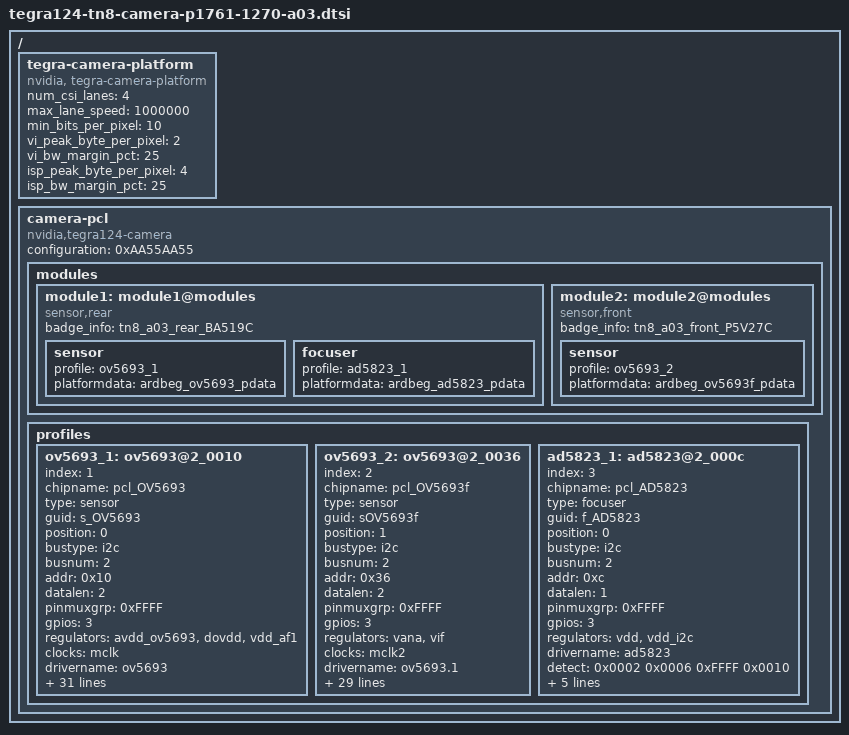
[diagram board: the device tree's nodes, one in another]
/*
 * Copyright (c) 2016, NVIDIA CORPORATION.  All rights reserved.
 *
 * This program is free software; you can redistribute it and/or modify it
 * under the terms and conditions of the GNU General Public License,
 * version 2, as published by the Free Software Foundation.
 *
 * This program is distributed in the hope it will be useful, but WITHOUT
 * ANY WARRANTY; without even the implied warranty of MERCHANTABILITY or
 * FITNESS FOR A PARTICULAR PURPOSE.  See the GNU General Public License for
 * more details.
 *
 * arch/arm/boot/dts/tegra124-platforms/tegra124-tn8-camera-p1761-1270-a00.dtsi
 */

#include <dt-bindings/media/camera.h>

/ {
	tegra-camera-platform {
		compatible = "nvidia, tegra-camera-platform";
		/**
		* Physical settings to calculate max ISO BW
		*
		* num_csi_lanes = <>;
		* Total number of CSI lanes when all cameras are active
		*
		* max_lane_speed = <>;
		* Max lane speed in Kbit/s
		*
		* min_bits_per_pixel = <>;
		* Min bits per pixel
		*
		* vi_peak_byte_per_pixel = <>;
		* Max byte per pixel for the VI ISO case
		*
		* vi_bw_margin_pct = <>;
		* Vi bandwidth margin in percentage
		*
		* isp_peak_byte_per_pixel = <>;
		* Max byte per pixel for the ISP ISO case
		*
		* isp_bw_margin_pct = <>;
		* Isp bandwidth margin in percentage
		*/
		num_csi_lanes = <4>;
		max_lane_speed = <1000000>;
		min_bits_per_pixel = <10>;
		vi_peak_byte_per_pixel = <2>;
		vi_bw_margin_pct = <25>;
		isp_peak_byte_per_pixel = <4>;
		isp_bw_margin_pct = <25>;
	};

	camera-pcl {
		compatible = "nvidia,tegra124-camera", "simple-bus";
		configuration = <0xAA55AA55>;

		modules {
			module1: module1@modules {
				compatible = "sensor,rear";
				badge_info = "tn8_a03_rear_BA519C";

				sensor {
					profile = <&ov5693_1>;
					platformdata = "ardbeg_ov5693_pdata";
				};
				focuser {
					profile = <&ad5823_1>;
					platformdata = "ardbeg_ad5823_pdata";
				};
			};
			module2: module2@modules {
				compatible = "sensor,front";
				badge_info = "tn8_a03_front_P5V27C";

				sensor {
					profile = <&ov5693_2>;
					platformdata = "ardbeg_ov5693f_pdata";
				};
			};
		};

		profiles {
			ov5693_1: ov5693@2_0010 {
				index = <1>;
				chipname = "pcl_OV5693";
				type = "sensor";
				guid = "s_OV5693";
				position = <0>;
				bustype = "i2c";
				busnum = <2>;
				addr = <0x10>;
				datalen = <2>;
				pinmuxgrp = <0xFFFF>;
				gpios = <3>;
				regulators = "avdd_ov5693", "dovdd", "vdd_af1";
				clocks = "mclk";
				drivername = "ov5693";
				detect = <0x0002 0x300A 0xFFFF 0x5690>;
				devid = <0x5693>;
				poweron = <
					CAMERA_IND_CLK_SET(10000)
					CAMERA_GPIO_CLR(221)
					CAMERA_WAITMS(1)
					CAMERA_REGULATOR_ON(0)
					CAMERA_REGULATOR_ON(2)
					CAMERA_REGULATOR_ON(1)
					CAMERA_WAITMS(1)
					CAMERA_GPIO_SET(221)
					CAMERA_WAITMS(10)
					CAMERA_END
					>;
				poweroff = <
					CAMERA_IND_CLK_CLR
					CAMERA_GPIO_CLR(221)
					CAMERA_WAITUS(10)
					CAMERA_REGULATOR_OFF(1)
					CAMERA_REGULATOR_OFF(2)
					CAMERA_REGULATOR_OFF(0)
					CAMERA_END
					>;
				/* sensor capabilities */
				cap-version = <0x34340002>;
				cap-identifier = "OV5693";
				cap-sensor_nvc_interface = <3>;
				cap-pixel_types = <0x2101>;
				cap-orientation = <1>;
				cap-direction = <0>;
				cap-initial_clock_rate_khz = <6000>;
				cap-h_sync_edge = <0>;
				cap-v_sync_edge = <0>;
				cap-mclk_on_vgp0 = <0>;
				cap-csi_port = <0>;
				cap-data_lanes = <2>;
				cap-virtual_channel_id = <0>;
				cap-discontinuous_clk_mode = <1>;
				cap-cil_threshold_settle = <0>;
				cap-min_blank_time_width = <16>;
				cap-min_blank_time_height = <16>;
				cap-preferred_mode_index = <0>;
				cap-external_clock_khz_0 = <24000>;
				cap-clock_multiplier_0 = <8000000>;
				cap-external_clock_khz_1 = <0>;
				cap-clock_multiplier_1 = <0>;
				cap-hdr-enabled;
				cap-focuser_guid = <
					0x665f4144
					0x35383233
				>;
				cap-torch_guid = <
					0x6c5f4e56
					0x43414d30
				>;
			};
			ov5693_2: ov5693@2_0036 {
				index = <2>;
				chipname = "pcl_OV5693f";
				type = "sensor";
				guid = "sOV5693f";
				position = <1>;
				bustype = "i2c";
				busnum = <2>;
				addr = <0x36>;
				datalen = <2>;
				pinmuxgrp = <0xFFFF>;
				gpios = <3>;
				regulators = "vana", "vif";
				clocks = "mclk2";
				drivername = "ov5693.1";
				detect = <0x0002 0x300A 0xFFFF 0x5690>;
				devid = <0x5693>;
				poweron = <
					CAMERA_IND_CLK_SET(10000)
					CAMERA_GPIO_CLR(219)
					CAMERA_GPIO_CLR(222)
					CAMERA_WAITMS(1)
					CAMERA_REGULATOR_ON(0)
					CAMERA_REGULATOR_ON(1)
					CAMERA_WAITMS(1)
					CAMERA_GPIO_SET(222)
					CAMERA_GPIO_SET(219)
					CAMERA_WAITMS(10)
					CAMERA_END
					>;
				poweroff = <
					CAMERA_IND_CLK_CLR
					CAMERA_GPIO_CLR(222)
					CAMERA_GPIO_CLR(219)
					CAMERA_WAITUS(10)
					CAMERA_REGULATOR_OFF(1)
					CAMERA_REGULATOR_OFF(0)
					CAMERA_END
					>;
				/* sensor capabilities */
				cap-version = <0x34340002>;
				cap-identifier = "OV5693.1";
				cap-sensor_nvc_interface = <4>;
				cap-pixel_types = <0x2101>;
				cap-orientation = <3>;
				cap-direction = <1>;
				cap-initial_clock_rate_khz = <6000>;
				cap-h_sync_edge = <0>;
				cap-v_sync_edge = <0>;
				cap-mclk_on_vgp0 = <0>;
				cap-csi_port = <1>;
				cap-data_lanes = <2>;
				cap-virtual_channel_id = <0>;
				cap-discontinuous_clk_mode = <1>;
				cap-cil_threshold_settle = <0>;
				cap-min_blank_time_width = <16>;
				cap-min_blank_time_height = <16>;
				cap-preferred_mode_index = <0>;
				cap-external_clock_khz_0 = <24000>;
				cap-clock_multiplier_0 = <8000000>;
				cap-external_clock_khz_1 = <0>;
				cap-clock_multiplier_1 = <0>;
				cap-hdr-enabled;
			};
			ad5823_1: ad5823@2_000c {
				index = <3>;
				chipname = "pcl_AD5823";
				type = "focuser";
				guid = "f_AD5823";
				position = <0>;
				bustype = "i2c";
				busnum = <2>;
				addr = <0xc>;
				datalen = <1>;
				pinmuxgrp = <0xFFFF>;
				gpios = <3>;
				regulators = "vdd", "vdd_i2c";
				drivername = "ad5823";
				detect = <0x0002 0x0006 0xFFFF 0x0010>;
				devid = <0x5823>;
				poweron = <
					CAMERA_REGULATOR_ON(1)
					CAMERA_REGULATOR_ON(0)
					CAMERA_WAITUS(10)
					CAMERA_GPIO_SET(223)
					CAMERA_WAITUS(10)
					CAMERA_END
					>;
				poweroff = <
					CAMERA_REGULATOR_OFF(0)
					CAMERA_REGULATOR_OFF(1)
					CAMERA_GPIO_CLR(223)
					CAMERA_WAITUS(10)
					CAMERA_END
					>;
			};
		};
	};
};

